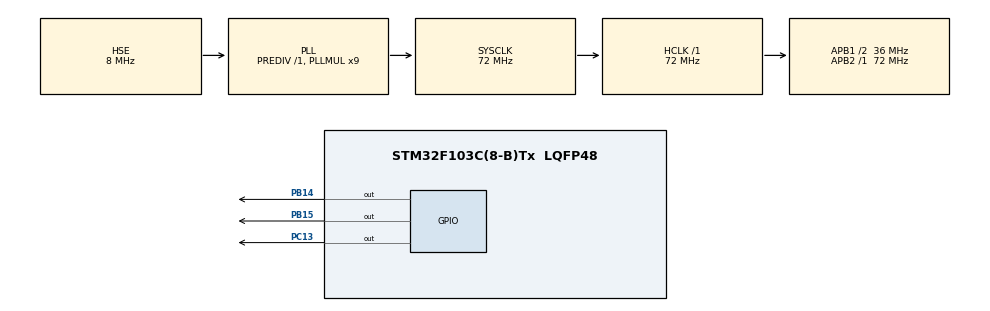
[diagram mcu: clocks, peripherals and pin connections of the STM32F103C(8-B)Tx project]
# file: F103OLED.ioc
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FREERTOS.Tasks01=oled,24,128,StartDefaultTask,Default,NULL,Dynamic,NULL,NULL;LED,8,128,StartTask02,Default,NULL,Dynamic,NULL,NULL
Mcu.Family=STM32F1
Mcu.Name=STM32F103C(8-B)Tx
Mcu.Package=LQFP48
NVIC.PriorityGroup=NVIC_PRIORITYGROUP_4
NVIC.TIM2_IRQn=true\:15\:0\:false\:false\:true\:false\:false\:true
NVIC.TimeBase=TIM2_IRQn
NVIC.TimeBaseIP=TIM2
PA13.Mode=Trace_Asynchronous_SW
PA13.Signal=SYS_JTMS-SWDIO
PA14.Mode=Trace_Asynchronous_SW
PA14.Signal=SYS_JTCK-SWCLK
PB14.GPIO_ModeDefaultOutputPP=GPIO_MODE_OUTPUT_PP
PB14.GPIO_PuPd=GPIO_NOPULL
PB14.Signal=GPIO_Output
PB15.GPIO_PuPd=GPIO_NOPULL
PB15.Signal=GPIO_Output
PB3.Mode=Trace_Asynchronous_SW
PB3.Signal=SYS_JTDO-TRACESWO
PC13-TAMPER-RTC.GPIO_ModeDefaultOutputPP=GPIO_MODE_OUTPUT_PP
PC13-TAMPER-RTC.GPIO_Speed=GPIO_SPEED_FREQ_MEDIUM
PC13-TAMPER-RTC.PinState=GPIO_PIN_SET
PC13-TAMPER-RTC.Signal=GPIO_Output
PC14-OSC32_IN.Mode=LSE-External-Oscillator
PC14-OSC32_IN.Signal=RCC_OSC32_IN
PC15-OSC32_OUT.Mode=LSE-External-Oscillator
PC15-OSC32_OUT.Signal=RCC_OSC32_OUT
PD0-OSC_IN.Mode=HSE-External-Oscillator
PD0-OSC_IN.Signal=RCC_OSC_IN
PD1-OSC_OUT.Mode=HSE-External-Oscillator
PD1-OSC_OUT.Signal=RCC_OSC_OUT
ProjectManager.HeapSize=0x200
ProjectManager.StackSize=0x400
ProjectManager.TargetToolchain=SW4STM32
RCC.AHBFreq_Value=72000000
RCC.APB1CLKDivider=RCC_HCLK_DIV2
RCC.APB1Freq_Value=36000000
RCC.APB1TimFreq_Value=72000000
RCC.APB2Freq_Value=72000000
RCC.APB2TimFreq_Value=72000000
RCC.HCLKFreq_Value=72000000
RCC.PLLMUL=RCC_PLL_MUL9
RCC.PLLSourceVirtual=RCC_PLLSOURCE_HSE
RCC.SYSCLKFreq_VALUE=72000000
RCC.SYSCLKSource=RCC_SYSCLKSOURCE_PLLCLK
RCC.USBFreq_Value=72000000
VP_FREERTOS_VS_CMSIS_V2.Mode=CMSIS_V2
VP_SYS_VS_tim2.Mode=TIM2
board=custom

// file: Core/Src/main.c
/* USER CODE BEGIN Header */
/**
  ******************************************************************************
  * @file           : main.c
  * @brief          : Main program body
  ******************************************************************************
  * @attention
  *
  * <h2><center>&copy; Copyright (c) 2023 STMicroelectronics.
  * All rights reserved.</center></h2>
  *
  * This software component is licensed by ST under BSD 3-Clause license,
  * the "License"; You may not use this file except in compliance with the
  * License. You may obtain a copy of the License at:
  *                        opensource.org/licenses/BSD-3-Clause
  *
  ******************************************************************************
  */
/* USER CODE END Header */
#include "main.h"
#include "cmsis_os.h"
#include "gpio.h"

void SystemClock_Config(void);
void MX_FREERTOS_Init(void);

int main(void)
{

  /* MCU Configuration--------------------------------------------------------*/

  /* Reset of all peripherals, Initializes the Flash interface and the Systick. */
  HAL_Init();

  /* Configure the system clock */
  SystemClock_Config();

  /* Initialize all configured peripherals */
  MX_GPIO_Init();

  /* Init scheduler */
  osKernelInitialize();  /* Call init function for freertos objects (in freertos.c) */
  MX_FREERTOS_Init();
  /* Start scheduler */
  osKernelStart();

  /* We should never get here as control is now taken by the scheduler */
  /* Infinite loop */
  while (1)
  {

  }
}

void SystemClock_Config(void)
{
  RCC_OscInitTypeDef RCC_OscInitStruct = {0};
  RCC_ClkInitTypeDef RCC_ClkInitStruct = {0};

  /** Initializes the RCC Oscillators according to the specified parameters
  * in the RCC_OscInitTypeDef structure.
  */
  RCC_OscInitStruct.OscillatorType = RCC_OSCILLATORTYPE_HSE;
  RCC_OscInitStruct.HSEState = RCC_HSE_ON;
  RCC_OscInitStruct.HSEPredivValue = RCC_HSE_PREDIV_DIV1;
  RCC_OscInitStruct.HSIState = RCC_HSI_ON;
  RCC_OscInitStruct.PLL.PLLState = RCC_PLL_ON;
  RCC_OscInitStruct.PLL.PLLSource = RCC_PLLSOURCE_HSE;
  RCC_OscInitStruct.PLL.PLLMUL = RCC_PLL_MUL9;
  if (HAL_RCC_OscConfig(&RCC_OscInitStruct) != HAL_OK)
  {
    Error_Handler();
  }
  /** Initializes the CPU, AHB and APB buses clocks
  */
  RCC_ClkInitStruct.ClockType = RCC_CLOCKTYPE_HCLK|RCC_CLOCKTYPE_SYSCLK
                              |RCC_CLOCKTYPE_PCLK1|RCC_CLOCKTYPE_PCLK2;
  RCC_ClkInitStruct.SYSCLKSource = RCC_SYSCLKSOURCE_PLLCLK;
  RCC_ClkInitStruct.AHBCLKDivider = RCC_SYSCLK_DIV1;
  RCC_ClkInitStruct.APB1CLKDivider = RCC_HCLK_DIV2;
  RCC_ClkInitStruct.APB2CLKDivider = RCC_HCLK_DIV1;

  if (HAL_RCC_ClockConfig(&RCC_ClkInitStruct, FLASH_LATENCY_2) != HAL_OK)
  {
    Error_Handler();
  }
}

void HAL_TIM_PeriodElapsedCallback(TIM_HandleTypeDef *htim)
{
  if (htim->Instance == TIM2) {
    HAL_IncTick();
  }
}

void Error_Handler(void)
{
  __disable_irq();
  while (1)
  {
  }
}

/************************ (C) COPYRIGHT STMicroelectronics *****END OF FILE****/

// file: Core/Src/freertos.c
/* USER CODE BEGIN Header */
/**
  ******************************************************************************
  * File Name          : freertos.c
  * Description        : Code for freertos applications
  ******************************************************************************
  * @attention
  *
  * <h2><center>&copy; Copyright (c) 2023 STMicroelectronics.
  * All rights reserved.</center></h2>
  *
  * This software component is licensed by ST under Ultimate Liberty license
  * SLA0044, the "License"; You may not use this file except in compliance with
  * the License. You may obtain a copy of the License at:
  *                             www.st.com/SLA0044
  *
  ******************************************************************************
  */
/* USER CODE END Header */

#include "FreeRTOS.h"
#include "task.h"
#include "main.h"
#include "cmsis_os.h"

/* USER CODE BEGIN Includes */
#include"oled.h"
#include"u8g2.h"
#include"WALL_E.h"
/* USER CODE END Includes */

/* USER CODE BEGIN PTD */
u8g2_t u8g2;
/* USER CODE END PTD */

/* USER CODE BEGIN PD */
short x=10,y=10;
typedef struct
{
    char * str;
}SET_LIST;

SET_LIST list[]={
        {"CAR_SETING"},
        {"TEMP"},
        {"BMP280"},
        {"BEEP"},
};

/* USER CODE END PD */

/* Definitions for oled */
osThreadId_t oledHandle;
const osThreadAttr_t oled_attributes = {
  .name = "oled",
  .stack_size = 128 * 4,
  .priority = (osPriority_t) osPriorityNormal,
};
/* Definitions for LED */
osThreadId_t LEDHandle;
const osThreadAttr_t LED_attributes = {
  .name = "LED",
  .stack_size = 128 * 4,
  .priority = (osPriority_t) osPriorityLow,
};

/* USER CODE BEGIN FunctionPrototypes */

void testDrawPixelToFillScreen()
{
    int t = 1000;
    u8g2_ClearBuffer(&u8g2);
    for (int j = 0; j < 64; j++)
    {
        for (int i = 0; i < 128; i++)
        {
            u8g2_DrawPixel(&u8g2,i, j);
        }
    }
    do {
    u8g2_SendBuffer(&u8g2);
    HAL_Delay(1000);
    }while (0);
}

void my_u8g2_init(void)
{
    u8g2_init(&u8g2);

    u8g2_FirstPage(&u8g2);
    u8g2_ClearBuffer(&u8g2);
    do
    {
        for(int i=20;i>12;i--)
        {
            u8g2_DrawCircle(&u8g2,64,32,i,U8G2_DRAW_ALL);
            HAL_Delay(200);
            u8g2_SendBuffer(&u8g2);
        }

    }while(u8g2_NextPage(&u8g2));

    u8g2_ClearBuffer(&u8g2);
    u8g2_DrawXBMP(&u8g2, 0, 0, wall_e_bmp01_x, wall_e_bmp01_y, wall_e_bmp01);
    u8g2_SendBuffer(&u8g2);
    HAL_Delay(500);
}

/* USER CODE END FunctionPrototypes */

void StartDefaultTask(void *argument);
void StartTask02(void *argument);

void MX_FREERTOS_Init(void); /* (MISRA C 2004 rule 8.1) */

void MX_FREERTOS_Init(void) {

  /* Create the thread(s) */
  /* creation of oled */
  oledHandle = osThreadNew(StartDefaultTask, NULL, &oled_attributes);

  /* creation of LED */
  LEDHandle = osThreadNew(StartTask02, NULL, &LED_attributes);

}

void StartDefaultTask(void *argument)
{

  /* USER CODE BEGIN StartDefaultTask */
    my_u8g2_init();
    u8g2_ClearBuffer(&u8g2);
    u8g2_SetFont(&u8g2,u8g2_font_ncenB10_tr);
    u8g2_DrawStr(&u8g2,0,30,"HELLO WORLD!!");
    u8g2_SendBuffer(&u8g2);
    HAL_Delay(500);
  /* Infinite loop */
  for(;;)
  {

//      testDrawPixelToFillScreen();
      uint8_t listlen=sizeof (list)/sizeof (SET_LIST);
    u8g2_SetFont(&u8g2,u8g2_font_ncenB08_tr);

   u8g2_ClearBuffer(&u8g2);
   for(int i=0;i<listlen;i++)
   {
       u8g2_DrawStr(&u8g2,x,y*i+16,list[i].str);
   }
      u8g2_DrawStr(&u8g2,110,16,"*");
      u8g2_SendBuffer(&u8g2);

    osDelay(1);

  }
  /* USER CODE END StartDefaultTask */
}

void StartTask02(void *argument)
{
  /* USER CODE BEGIN StartTask02 */
  /* Infinite loop */
  for(;;)
  {
      HAL_GPIO_WritePin(GPIOC,GPIO_PIN_13,GPIO_PIN_RESET);

   vTaskDelay(1);
  }
  /* USER CODE END StartTask02 */
}

/************************ (C) COPYRIGHT STMicroelectronics *****END OF FILE****/
